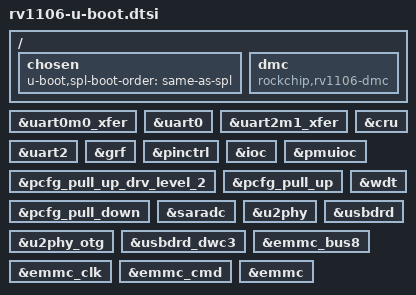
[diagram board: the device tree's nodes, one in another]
/*
 * (C) Copyright 2022 Rockchip Electronics Co., Ltd
 * (C) Copyright 2025 Dmitrii Sharshakov
 *
 * SPDX-License-Identifier:     GPL-2.0+
 */

#include "rockchip-u-boot.dtsi"

/ {
	chosen {
		u-boot,spl-boot-order = "same-as-spl", &emmc;
	};

	dmc {
		compatible = "rockchip,rv1106-dmc";
		bootph-all;
	};
};

&uart0m0_xfer {
	bootph-all;
};
&uart0 {
	bootph-all;
};

&uart2m1_xfer {
	bootph-all;
};
&uart2 {
	bootph-all;
};

&cru {
	bootph-all;
};

&grf {
	bootph-all;
};

&pinctrl {
	bootph-all;
};

&ioc {
	bootph-all;
};

&pmuioc {
	bootph-all;
};

&pcfg_pull_up_drv_level_2 {
	bootph-all;
};

&pcfg_pull_up {
	bootph-all;
};

&pcfg_pull_down{
	bootph-all;
};

&saradc {
	bootph-all;
};

&wdt {
	bootph-all;
};

&u2phy {
	bootph-all;
};

&u2phy_otg {
	bootph-all;
};

&usbdrd {
	bootph-all;
};
&usbdrd_dwc3 {
	bootph-all;
};

&emmc_bus8 {
	bootph-all;
};
&emmc_clk {
	bootph-all;
};
&emmc_cmd {
	bootph-all;
};
&emmc {
	bootph-all;
};
